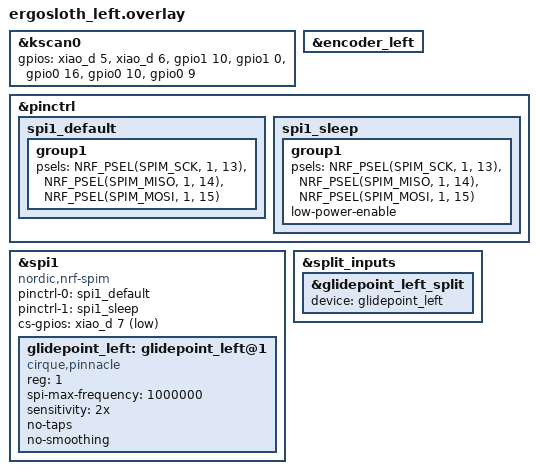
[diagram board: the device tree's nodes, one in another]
/*
 * Copyright (c) 2020 Pete Johanson
 *
 * SPDX-License-Identifier: MIT
 */

#include "ergosloth.dtsi"
#include <input/processors.dtsi>

&kscan0 {
    gpios
        = <&xiao_d 5 (GPIO_ACTIVE_HIGH)>
        , <&xiao_d 6 (GPIO_ACTIVE_HIGH)>
        , <&gpio1 10 (GPIO_ACTIVE_HIGH)>
        , <&gpio1  0 (GPIO_ACTIVE_HIGH)>
        , <&gpio0 16 (GPIO_ACTIVE_HIGH)>
        , <&gpio0 10 (GPIO_ACTIVE_HIGH)>
        , <&gpio0  9 (GPIO_ACTIVE_HIGH)>
        ;
};

&encoder_left {
    status = "okay";
};

//-----------------------------------------------------------

&pinctrl {
    spi1_default: spi1_default {
        group1 {
            psels = <NRF_PSEL(SPIM_SCK, 1, 13)>, // xiao D8, see posix_seeed_xiao.overlay in zmk source
            <NRF_PSEL(SPIM_MISO, 1, 14)>, // xiao D9 
            <NRF_PSEL(SPIM_MOSI, 1, 15)>; // xiao D10
        };
    };

    spi1_sleep: spi1_sleep {
        group1 {
            psels = <NRF_PSEL(SPIM_SCK, 1, 13)>,
                    <NRF_PSEL(SPIM_MISO, 1, 14)>,
                    <NRF_PSEL(SPIM_MOSI, 1, 15)>;
            low-power-enable;
        };
    };
};

&spi1 {
    status = "okay";
    compatible = "nordic,nrf-spim";
    pinctrl-0 = <&spi1_default>;
    pinctrl-1 = <&spi1_sleep>;
    pinctrl-names = "default", "sleep";
    cs-gpios = <&xiao_d 7 GPIO_ACTIVE_LOW>;

    glidepoint_left: glidepoint_left@1 {
        compatible = "cirque,pinnacle";
        status = "okay";
        reg = <1>;
        spi-max-frequency = <1000000>;
        sensitivity = "2x";
        no-taps;
        no-smoothing;
        //absolute-mode;
    };
};

&split_inputs {
    #address-cells = <1>;
    #size-cells = <0>;

    &glidepoint_left_split {
        device = <&glidepoint_left>;
    };
};
//------------------------------------------------------------
